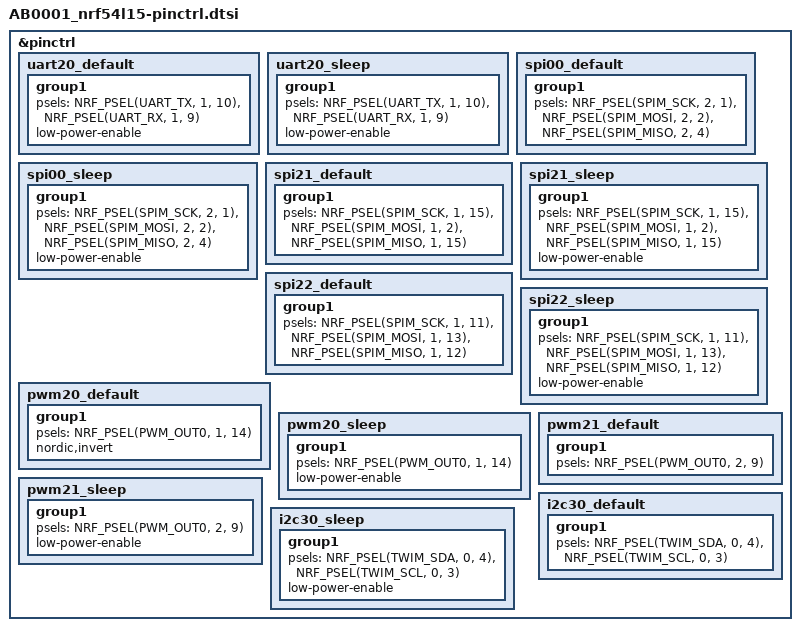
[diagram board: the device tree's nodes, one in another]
/*
 * Copyright (c) 2024 Nordic Semiconductor
 * SPDX-License-Identifier: Apache-2.0
 */

&pinctrl {
// UART System Monitor -------------------------------------------
	uart20_default: uart20_default {
		group1 {
			psels = <NRF_PSEL(UART_TX, 1, 10)>,
					<NRF_PSEL(UART_RX, 1, 9)>;

			low-power-enable;
		};
	};

	uart20_sleep: uart20_sleep {
		group1 {
			psels = <NRF_PSEL(UART_TX, 1, 10)>,
					<NRF_PSEL(UART_RX, 1, 9)>;

			low-power-enable;
		};
	};

// SPI for external Memory --------------------
	spi00_default: spi00_default {
		group1 {
			psels = <NRF_PSEL(SPIM_SCK, 2, 1)>,
			        <NRF_PSEL(SPIM_MOSI, 2, 2)>,
			        <NRF_PSEL(SPIM_MISO, 2, 4)>;
		};
	};

	spi00_sleep: spi00_sleep {
		group1 {
			psels = <NRF_PSEL(SPIM_SCK, 2, 1)>,
			        <NRF_PSEL(SPIM_MOSI, 2, 2)>,
			        <NRF_PSEL(SPIM_MISO, 2, 4)>;
			low-power-enable;
		};
	};
// SPI für digitale LED --------------------
	spi21_default: spi21_default {
		group1 {
			psels = <NRF_PSEL(SPIM_SCK, 1, 15)>,
			        <NRF_PSEL(SPIM_MOSI, 1, 2)>,
			        <NRF_PSEL(SPIM_MISO, 1, 15)>;
		};
	};

	spi21_sleep: spi21_sleep {
		group1 {
			psels = <NRF_PSEL(SPIM_SCK, 1, 15)>,
			        <NRF_PSEL(SPIM_MOSI, 1, 2)>,
			        <NRF_PSEL(SPIM_MISO, 1, 15)>;
			low-power-enable;
		};
	};


// SPI for Fingerprint NFC Reader and UWB Chip --------------------
	spi22_default: spi22_default {
		group1 {
			psels = <NRF_PSEL(SPIM_SCK, 1, 11)>,
			        <NRF_PSEL(SPIM_MOSI, 1, 13)>,
			        <NRF_PSEL(SPIM_MISO, 1, 12)>;
		};
	};

	spi22_sleep: spi22_sleep {
		group1 {
			psels = <NRF_PSEL(SPIM_SCK, 1, 11)>,
			        <NRF_PSEL(SPIM_MOSI, 1, 13)>,
			        <NRF_PSEL(SPIM_MISO, 1, 12)>;
			low-power-enable;
		};
	};

// PWM for buzzer --------------------
	pwm20_default: pwm20_default {
		group1 {
			psels = <NRF_PSEL(PWM_OUT0, 1, 14)>;
			nordic,invert;
		};
	};

	pwm20_sleep: pwm20_sleep {
		group1 {
			psels = <NRF_PSEL(PWM_OUT0, 1, 14)>;
			low-power-enable;
		};
	};

// PWM for vibration --------------------
	pwm21_default: pwm21_default {
		group1 {
			psels = <NRF_PSEL(PWM_OUT0, 2, 9)>;
		};
	};

	pwm21_sleep: pwm21_sleep {
		group1 {
			psels = <NRF_PSEL(PWM_OUT0, 2, 9)>;
			low-power-enable;
		};
	};

// I2C for captouch controller
	i2c30_default: i2c30_default {
		group1 {
			psels = <NRF_PSEL(TWIM_SDA, 0, 4)>,
					<NRF_PSEL(TWIM_SCL, 0, 3)>;
		};
	};

	i2c30_sleep: i2c30_sleep {
		group1 {
			psels = <NRF_PSEL(TWIM_SDA, 0, 4)>,
					<NRF_PSEL(TWIM_SCL, 0, 3)>;
			low-power-enable;
		};
	};
};
